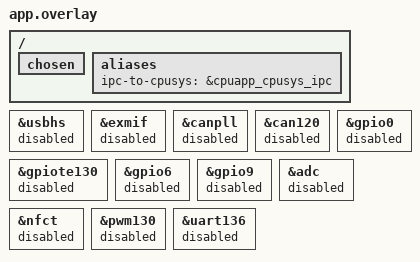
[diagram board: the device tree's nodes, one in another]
/*
 * Copyright (c) 2025 Nordic Semiconductor ASA
 * SPDX-License-Identifier: LicenseRef-Nordic-5-Clause
 */

/* Disable some of the default nRF54H20 DK configuration.
 *
 * Ideally, doing this shouldn't be needed, but it prevents unused resources
 * from being included in the autogenerated UICR.PERIPHCONF.
 */

/ {
	/delete-node/ aliases;
	/delete-node/ buttons;
	/delete-node/ leds;
	/delete-node/ pwmleds;

	chosen {
		/delete-property/ zephyr,serial;
	};

	aliases {
		/* Required by NRFS_LOCAL_DOMAIN */
		ipc-to-cpusys = &cpuapp_cpusys_ipc;
	};
};

&usbhs {
	status = "disabled";
};

&exmif {
	status = "disabled";
};

&canpll {
	status = "disabled";
};

&can120 {
	status = "disabled";
};

&gpiote130 {
	status = "disabled";
	/delete-property/ owned-channels;
};

&gpio0 {
	status = "disabled";
};

&gpio6 {
	status = "disabled";
};

&gpio9 {
	status = "disabled";
};

&adc {
	status = "disabled";
};

&nfct {
	status = "disabled";
};

&pwm130 {
	status = "disabled";
};

&uart136 {
	status = "disabled";
};
